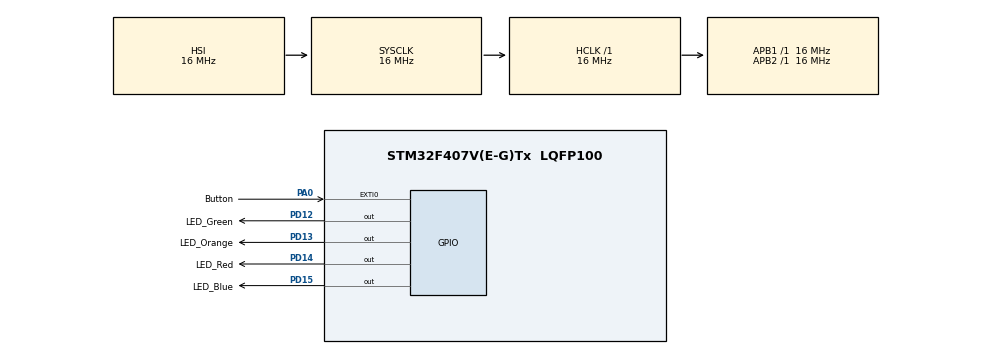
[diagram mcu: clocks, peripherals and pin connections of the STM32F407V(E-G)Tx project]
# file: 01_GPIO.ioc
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Mcu.Family=STM32F4
PD12.GPIO_Label=LED_Green
RCC.CortexFreq_Value=16000000
PD15.GPIO_Label=LED_Blue
PA0-WKUP.GPIO_ModeDefaultEXTI=GPIO_MODE_IT_RISING_FALLING
ProjectManager.StackSize=0x400
PA0-WKUP.GPIO_Label=Button
PA0-WKUP.Signal=GPXTI0
PD13.Signal=GPIO_Output
ProjectManager.TargetToolchain=STM32CubeIDE
RCC.LSE_VALUE=32768
RCC.AHBFreq_Value=16000000
RCC.HSE_VALUE=25000000
board=custom
RCC.VCOOutputFreq_Value=192000000
RCC.APB2Freq_Value=16000000
PD14.GPIO_Label=LED_Red
Mcu.Name=STM32F407V(E-G)Tx
PD14.Signal=GPIO_Output
NVIC.EXTI0_IRQn=true\:0\:0\:false\:false\:true\:true\:true
RCC.SYSCLKFreq_VALUE=16000000
PD13.GPIO_Label=LED_Orange
Mcu.Package=LQFP100
PD12.Signal=GPIO_Output
ProjectManager.HeapSize=0x200
RCC.HSI_VALUE=16000000
NVIC.PriorityGroup=NVIC_PRIORITYGROUP_4
RCC.APB1Freq_Value=16000000
PD15.Signal=GPIO_Output

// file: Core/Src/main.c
/* USER CODE BEGIN Header */
/**
  ******************************************************************************
  * @file           : main.c
  * @brief          : Main program body
  ******************************************************************************
  * @attention
  *
  * <h2><center>&copy; Copyright (c) 2021 STMicroelectronics.
  * All rights reserved.</center></h2>
  *
  * This software component is licensed by ST under BSD 3-Clause license,
  * the "License"; You may not use this file except in compliance with the
  * License. You may obtain a copy of the License at:
  *                        opensource.org/licenses/BSD-3-Clause
  *
  ******************************************************************************
  */
/* USER CODE END Header */
#include "main.h"

void SystemClock_Config(void);
static void MX_GPIO_Init(void);
/* USER CODE BEGIN PFP */
//void HAL_GPIO_EXTI_Callback(uint16_t GPIO_Pin);
void HAL_GPIO_EXTI_Callback(uint16_t GPIO_Pin) {
	static uint8_t state = 1;
	if (GPIO_Pin == Button_Pin) {

		if (state == 1) {
			HAL_GPIO_TogglePin(LED_Blue_GPIO_Port, LED_Blue_Pin);
		} else if (state == 2) {
			HAL_GPIO_TogglePin(LED_Green_GPIO_Port, LED_Green_Pin);
		} else if (state == 3) {
			HAL_GPIO_TogglePin(LED_Orange_GPIO_Port, LED_Orange_Pin);
		} else if (state == 4) {
			HAL_GPIO_TogglePin(LED_Red_GPIO_Port, LED_Red_Pin);
		}

		++state;
		if (state == 5) {
			state = 1;
		}

	}
}
//void HAL_GPIO_EXTI_Callback(uint16_t GPIO_Pin)
//{
//	if(GPIO_Pin == Button_Pin)
//	{
//		HAL_GPIO_WritePin(LED_Blue_GPIO_Port, LED_Blue_Pin, HAL_GPIO_ReadPin(Button_GPIO_Port, Button_Pin));
//		HAL_GPIO_WritePin(LED_Green_GPIO_Port, LED_Green_Pin, HAL_GPIO_ReadPin(Button_GPIO_Port, Button_Pin));
//		HAL_GPIO_WritePin(LED_Orange_GPIO_Port, LED_Orange_Pin, HAL_GPIO_ReadPin(Button_GPIO_Port, Button_Pin));
//		HAL_GPIO_WritePin(LED_Red_GPIO_Port, LED_Red_Pin, HAL_GPIO_ReadPin(Button_GPIO_Port, Button_Pin));
//	}
//}
/* USER CODE END PFP */

int main(void)
{

  /* MCU Configuration--------------------------------------------------------*/

  /* Reset of all peripherals, Initializes the Flash interface and the Systick. */
  HAL_Init();

  /* Configure the system clock */
  SystemClock_Config();

  /* Initialize all configured peripherals */
  MX_GPIO_Init();

  /* Infinite loop */
  while (1)
  {

    /* USER CODE BEGIN 3 */

//	  if(HAL_GPIO_ReadPin(Button_GPIO_Port, Button_Pin) == GPIO_PIN_SET)
//	  {
//		  HAL_GPIO_WritePin(LED_Blue_GPIO_Port, LED_Blue_Pin, GPIO_PIN_SET);
//		  HAL_GPIO_WritePin(LED_Orange_GPIO_Port, LED_Orange_Pin, GPIO_PIN_SET);
//		  HAL_GPIO_WritePin(LED_Red_GPIO_Port, LED_Red_Pin, GPIO_PIN_SET);
//		  HAL_GPIO_WritePin(LED_Green_GPIO_Port, LED_Green_Pin, GPIO_PIN_SET);
//	  }
//	  else
//	  {
//		  HAL_GPIO_WritePin(LED_Blue_GPIO_Port, LED_Blue_Pin, GPIO_PIN_RESET);
//		  HAL_GPIO_WritePin(LED_Orange_GPIO_Port, LED_Orange_Pin, GPIO_PIN_RESET);
//		  HAL_GPIO_WritePin(LED_Red_GPIO_Port, LED_Red_Pin, GPIO_PIN_RESET);
//		  HAL_GPIO_WritePin(LED_Green_GPIO_Port, LED_Green_Pin, GPIO_PIN_RESET);
//	  }
  }
  /* USER CODE END 3 */
}

void SystemClock_Config(void)
{
  RCC_OscInitTypeDef RCC_OscInitStruct = {0};
  RCC_ClkInitTypeDef RCC_ClkInitStruct = {0};

  /** Configure the main internal regulator output voltage
  */
  __HAL_RCC_PWR_CLK_ENABLE();
  __HAL_PWR_VOLTAGESCALING_CONFIG(PWR_REGULATOR_VOLTAGE_SCALE1);
  /** Initializes the RCC Oscillators according to the specified parameters
  * in the RCC_OscInitTypeDef structure.
  */
  RCC_OscInitStruct.OscillatorType = RCC_OSCILLATORTYPE_HSI;
  RCC_OscInitStruct.HSIState = RCC_HSI_ON;
  RCC_OscInitStruct.HSICalibrationValue = RCC_HSICALIBRATION_DEFAULT;
  RCC_OscInitStruct.PLL.PLLState = RCC_PLL_NONE;
  if (HAL_RCC_OscConfig(&RCC_OscInitStruct) != HAL_OK)
  {
    Error_Handler();
  }
  /** Initializes the CPU, AHB and APB buses clocks
  */
  RCC_ClkInitStruct.ClockType = RCC_CLOCKTYPE_HCLK|RCC_CLOCKTYPE_SYSCLK
                              |RCC_CLOCKTYPE_PCLK1|RCC_CLOCKTYPE_PCLK2;
  RCC_ClkInitStruct.SYSCLKSource = RCC_SYSCLKSOURCE_HSI;
  RCC_ClkInitStruct.AHBCLKDivider = RCC_SYSCLK_DIV1;
  RCC_ClkInitStruct.APB1CLKDivider = RCC_HCLK_DIV1;
  RCC_ClkInitStruct.APB2CLKDivider = RCC_HCLK_DIV1;

  if (HAL_RCC_ClockConfig(&RCC_ClkInitStruct, FLASH_LATENCY_0) != HAL_OK)
  {
    Error_Handler();
  }
}

static void MX_GPIO_Init(void)
{
  GPIO_InitTypeDef GPIO_InitStruct = {0};

  /* GPIO Ports Clock Enable */
  __HAL_RCC_GPIOA_CLK_ENABLE();
  __HAL_RCC_GPIOD_CLK_ENABLE();

  /*Configure GPIO pin Output Level */
  HAL_GPIO_WritePin(GPIOD, LED_Green_Pin|LED_Orange_Pin|LED_Red_Pin|LED_Blue_Pin, GPIO_PIN_RESET);

  /*Configure GPIO pin : Button_Pin */
  GPIO_InitStruct.Pin = Button_Pin;
  GPIO_InitStruct.Mode = GPIO_MODE_IT_RISING_FALLING;
  GPIO_InitStruct.Pull = GPIO_NOPULL;
  HAL_GPIO_Init(Button_GPIO_Port, &GPIO_InitStruct);

  /*Configure GPIO pins : LED_Green_Pin LED_Orange_Pin LED_Red_Pin LED_Blue_Pin */
  GPIO_InitStruct.Pin = LED_Green_Pin|LED_Orange_Pin|LED_Red_Pin|LED_Blue_Pin;
  GPIO_InitStruct.Mode = GPIO_MODE_OUTPUT_PP;
  GPIO_InitStruct.Pull = GPIO_NOPULL;
  GPIO_InitStruct.Speed = GPIO_SPEED_FREQ_LOW;
  HAL_GPIO_Init(GPIOD, &GPIO_InitStruct);

  /* EXTI interrupt init*/
  HAL_NVIC_SetPriority(EXTI0_IRQn, 0, 0);
  HAL_NVIC_EnableIRQ(EXTI0_IRQn);

}

/* USER CODE BEGIN 4 */
//void HAL_GPIO_EXTI_Callback(uint16_t GPIO_Pin)
//{
//	static uint8_t state = 1;
//		if (GPIO_Pin == Button_Pin) {
//
//			if (state == 1) {
//				HAL_GPIO_TogglePin(LED_Blue_GPIO_Port, LED_Blue_Pin);
//			} else if (state == 2) {
//				HAL_GPIO_TogglePin(LED_Green_GPIO_Port, LED_Green_Pin);
//			} else if (state == 3) {
//				HAL_GPIO_TogglePin(LED_Orange_GPIO_Port, LED_Orange_Pin);
//			} else if (state == 4) {
//				HAL_GPIO_TogglePin(LED_Red_GPIO_Port, LED_Red_Pin);
//			}
//
//			++state;
//			if (state == 5) {
//				state = 1;
//			}
//
//		}
//}
/* USER CODE END 4 */

void Error_Handler(void)
{
  __disable_irq();
  while (1)
  {
  }
}

/************************ (C) COPYRIGHT STMicroelectronics *****END OF FILE****/
